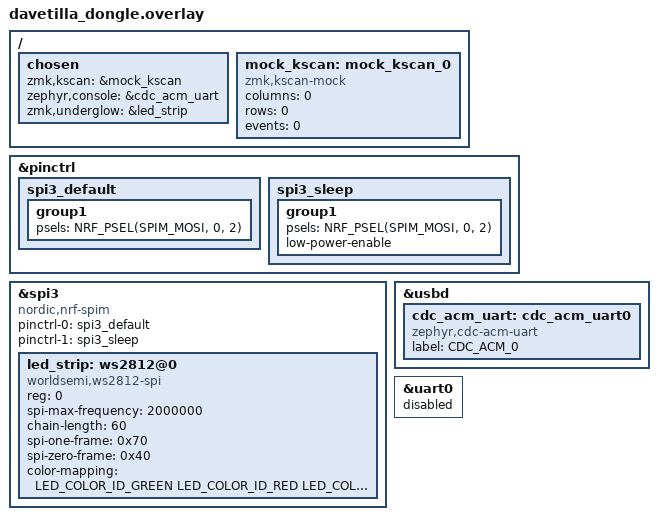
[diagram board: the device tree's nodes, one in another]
#include "davetilla.dtsi"
#include <dt-bindings/led/led.h>

/ {
    chosen {
        zmk,kscan = &mock_kscan;
        zephyr,console = &cdc_acm_uart;
        zmk,underglow = &led_strip;
    };

    mock_kscan: mock_kscan_0 {
        compatible = "zmk,kscan-mock";
        columns = <0>;
        rows = <0>;
        events = <0>;
    };
};

&pinctrl {
    spi3_default: spi3_default {
        group1 {
            psels = <NRF_PSEL(SPIM_MOSI, 0, 2)>;
        };
    };
    spi3_sleep: spi3_sleep {
        group1 {
            psels = <NRF_PSEL(SPIM_MOSI, 0, 2)>;
            low-power-enable;
        };
    };
};

&spi3 {
    compatible = "nordic,nrf-spim";
    status = "okay";
    pinctrl-0 = <&spi3_default>;
    pinctrl-1 = <&spi3_sleep>;
    pinctrl-names = "default", "sleep";

    led_strip: ws2812@0 {
        compatible = "worldsemi,ws2812-spi";
        reg = <0>;
        spi-max-frequency = <2000000>;  
        chain-length = <60>;
        spi-one-frame = <0x70>;         
        spi-zero-frame = <0x40>;        
        color-mapping = <LED_COLOR_ID_GREEN
                         LED_COLOR_ID_RED
                         LED_COLOR_ID_BLUE>;
    };
};


&usbd {
    cdc_acm_uart: cdc_acm_uart0 {
        compatible = "zephyr,cdc-acm-uart";
        label = "CDC_ACM_0";
    };
};

&uart0 {
    status = "disabled";
};



// vim: expandtab softtabstop=4 shiftwidth=4 filetype=devicetree
